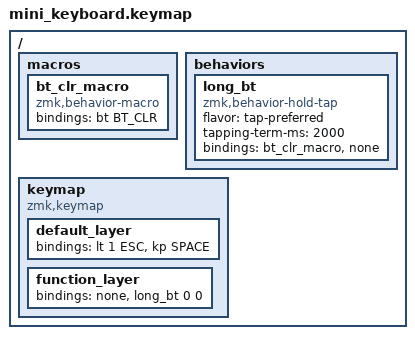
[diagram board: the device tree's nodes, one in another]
#include <behaviors.dtsi>
#include <dt-bindings/zmk/keys.h>
#include <dt-bindings/zmk/bt.h>
#include <dt-bindings/zmk/pointing.h>

/ {
    macros {
        bt_clr_macro: bt_clr_macro {
            compatible = "zmk,behavior-macro";
            #binding-cells = <0>;
            bindings = <&bt BT_CLR>;
        };
    };

    behaviors {
        // Safety hold for 2 seconds to Clear BT
        long_bt: long_bt {
            compatible = "zmk,behavior-hold-tap";
            #binding-cells = <2>;
            flavor = "tap-preferred";
            tapping-term-ms = <2000>;
            bindings = <&bt_clr_macro>, <&none>;
        };
    };

    // --- COMBOS REMOVED TO ELIMINATE DELAY ---

    keymap {
        compatible = "zmk,keymap";

        default_layer {
            bindings = <
                &lt 1 ESC    &kp SPACE
            >;
        };

        // This layer is active ONLY when holding the middle key
        function_layer {
            bindings = <
                &none    &long_bt 0 0
            >;
        };
    };
};
